CM_ "Toyota Yaris Hybrid 2014 (XP130, THS-II NoDSU) - reverse engineered from a candump (500kbps) captured on the";
CM_ "factory head-unit connector (28-pin, p/n 90980-12555, CAN-H=pin9/CAN-L=pin10), NOT the OBD-II diagnostic port.";
CM_ "Base messages taken from BogGyver/opendbc (tesla_unity_dev) toyota_nodsu_hybrid_pt_generated.dbc and empirically validated";
CM_ "against a real ~7min drive log (data/logs/session_0044.log). Additions for BRAKE_ANALOG (0x224) and";
CM_ "COMBO_METER_0x34 (0x618) are original findings from this project, not present in opendbc.";
CM_ "See docs/signal_findings.md for full validation methodology and confidence levels.";

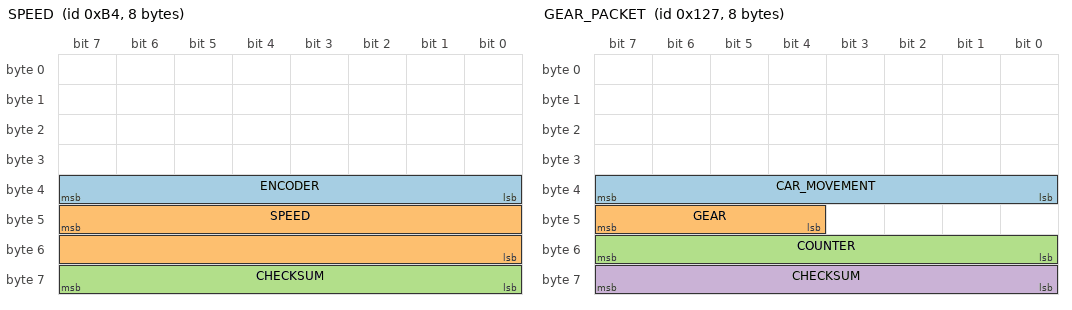
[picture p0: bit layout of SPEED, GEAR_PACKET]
BO_ 180 SPEED: 8 XXX
 SG_ ENCODER : 39|8@0+ (1,0) [0|255] "" XXX
 SG_ SPEED : 47|16@0+ (0.01,0) [0|250] "kph" XXX
 SG_ CHECKSUM : 63|8@0+ (1,0) [0|255] "" XXX

CM_ SG_ 180 SPEED "CONFIRMED. Validated against real 0->60->0 kph driving profile.";

BO_ 452 ENGINE_RPM: 8 XXX
 SG_ RPM : 7|16@0- (0.78125,0) [0|0] "rpm" XXX

CM_ SG_ 452 RPM "CONFIRMED. Oscillates 0/~1000-2000rpm matching ICE start/stop cycling typical of THS-II.";

BO_ 295 GEAR_PACKET: 8 XXX
 SG_ CAR_MOVEMENT : 39|8@0- (1,0) [0|255] "" XXX
 SG_ GEAR : 47|4@0+ (1,0) [0|15] "" XXX
 SG_ COUNTER : 55|8@0+ (1,0) [0|255] "" XXX
 SG_ CHECKSUM : 63|8@0+ (1,0) [0|255] "" XXX

VAL_ 295 GEAR 0 "P" 1 "R" 2 "N" 3 "D" 4 "B" ;
CM_ SG_ 295 GEAR "CONFIRMED, all 5 states observed across two independent logs. session_0044: P(0) 0-50.4s -> R(1) 50.4-60.1s -> D(3) 60.1s-end, with SPEED=0 while parked, a reverse bump (0->4.7kph) during the R phase and forward acceleration (0->10+kph) right after the D shift. session_0047: P(0) held ~98s at standstill -> N(2)->R(1)->N(2)->D(3) pull-out sequence -> D held for ~280s of real driving -> end-of-log full gear cycle R(1)->D(3)->B(4)->D(3)->N(2)->R(1)->D(3)->P(0), confirming B (Engine Brake) as well. NOTE: 0x127 was previously suspected to be a 'drive mode' counter; that counter is actually the CAR_MOVEMENT byte, a separate field in the same message.";

BO_ 560 BRAKE_MODULE2: 7 XXX
 SG_ BRAKE_PRESSED : 26|1@0+ (1,0) [0|1] "" XXX

CM_ SG_ 560 BRAKE_PRESSED "CONFIRMED. Transition timings correlate exactly with GEAR shifts and SPEED changes (brake held at standstill before/after each gear change).";

BO_ 548 BRAKE_ANALOG: 8 XXX
 SG_ BRAKE_VALUE : 32|16@0+ (1,0) [0|1023] "" XXX

CM_ BO_ 548 "STRONG HYPOTHESIS (not in any opendbc DBC - original finding). ID 0x224, not present in upstream Toyota DBCs (which define BRAKE_MODULE with pressure/position at 0x226, absent from this capture). Formula: value = (byte[4]<<8 | byte[5]), i.e. bits 32-47 as a big-endian 16-bit (effectively ~10-bit, max observed 537) quantity. Statistically: median=0 / mean=0.04 while BRAKE_PRESSED=0 (n=12027), median=62 / mean=154 / max=537 while BRAKE_PRESSED=1 (n=5731); 84% of pressed samples have value>5, 99.99% of released samples have value<=5. Strong correlation confirms this is a brake pedal analog signal (pressure and/or position), but exact physical units/scale are NOT confirmed.";

BO_ 581 GAS_PEDAL: 8 XXX
 SG_ GAS_PEDAL : 23|8@0+ (0.005,0) [0|1] "" XXX

CM_ SG_ 581 GAS_PEDAL "CONFIRMED. 0.0-0.35 (0-35%) range observed, closely tracking the accelerate/coast pattern of city driving and preceding each RPM/SPEED rise.";

BO_ 1553 UI_SETTING: 8 XXX
 SG_ UNITS : 26|2@0+ (1,0) [0|3] "" XXX
 SG_ ODOMETER : 43|20@0+ (1,0) [0|1048575] "" XXX

VAL_ 1553 UNITS 1 "km" 2 "miles" ;
CM_ SG_ 1553 ODOMETER "CONFIRMED but NOT remaining range. This is the TOTAL vehicle odometer (99552 -> 99555 km over the ~7min/~3km log, UNITS=km). No distance-to-empty / remaining-range signal or HV SOC% was found in this capture -- see docs/signal_findings.md section 2 for the negative-result justification.";

BO_ 1556 STEERING_LEVERS: 8 XXX
 SG_ TURN_SIGNALS : 29|2@0+ (1,0) [0|3] "" XXX
 SG_ HAZARD_LIGHT : 27|1@0+ (1,0) [0|1] "" XXX

VAL_ 1556 TURN_SIGNALS 3 "none" 2 "right" 1 "left" ;
CM_ SG_ 1556 TURN_SIGNALS "CONFIRMED. All 3 states (left/right/none) observed over the drive with plausible multi-second durations consistent with real indicator usage at turns.";

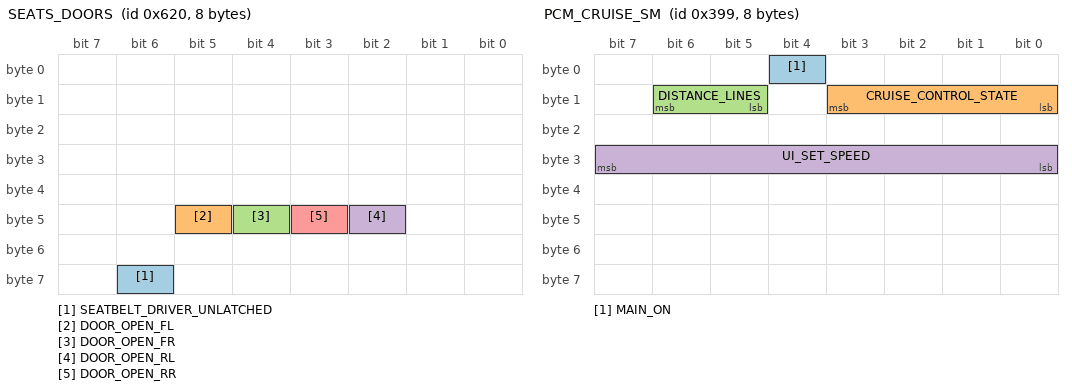
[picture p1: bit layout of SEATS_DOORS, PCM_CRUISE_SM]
BO_ 1568 SEATS_DOORS: 8 XXX
 SG_ SEATBELT_DRIVER_UNLATCHED : 62|1@0+ (1,0) [0|1] "" XXX
 SG_ DOOR_OPEN_FL : 45|1@0+ (1,0) [0|1] "" XXX
 SG_ DOOR_OPEN_FR : 44|1@0+ (1,0) [0|1] "" XXX
 SG_ DOOR_OPEN_RL : 42|1@0+ (1,0) [0|1] "" XXX
 SG_ DOOR_OPEN_RR : 43|1@0+ (1,0) [0|1] "" XXX

CM_ BO_ 1568 "CONFIRMED PRESENT, plausible (seatbelt toggles 0/1); doors never opened during this particular drive so DOOR_OPEN_* only show constant 0 in this log (not independently validated, but the message/bit layout is inherited verbatim from opendbc).";

BO_ 921 PCM_CRUISE_SM: 8 XXX
 SG_ MAIN_ON : 4|1@0+ (1,0) [0|1] "" XXX
 SG_ CRUISE_CONTROL_STATE : 11|4@0+ (1,0) [0|15] "" XXX
 SG_ DISTANCE_LINES : 14|2@0+ (1,0) [0|3] "" XXX
 SG_ UI_SET_SPEED : 31|8@0+ (1,0) [0|255] "" XXX

CM_ BO_ 921 "PRESENT but INACTIVE for the whole log (all-zero) -- cruise control was never engaged during capture, so fields could not be behaviourally validated beyond confirming the message exists at the expected ID/layout.";

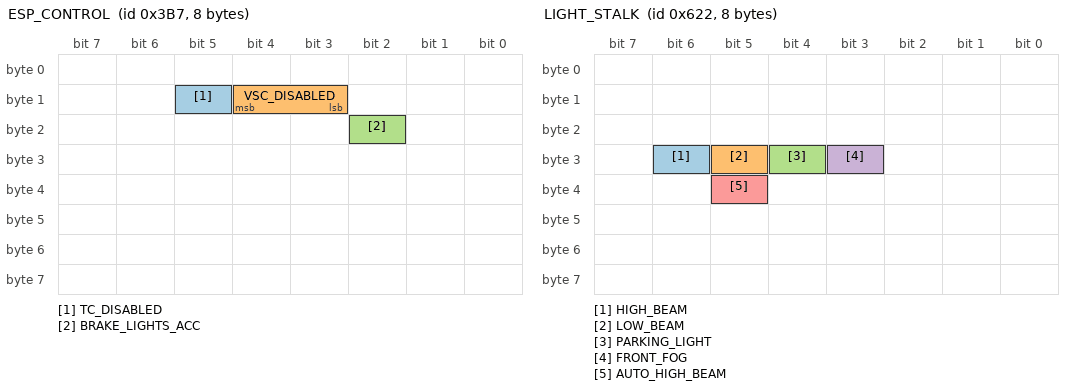
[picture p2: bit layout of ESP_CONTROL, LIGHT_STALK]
BO_ 951 ESP_CONTROL: 8 XXX
 SG_ TC_DISABLED : 13|1@0+ (1,0) [0|1] "" XXX
 SG_ VSC_DISABLED : 12|2@0+ (1,0) [0|1] "" XXX
 SG_ BRAKE_LIGHTS_ACC : 18|1@0+ (1,0) [0|1] "" XXX

CM_ BO_ 951 "PRESENT but INACTIVE for the whole log (no VSC/TC intervention occurred during this calm drive).";

BO_ 1570 LIGHT_STALK: 8 XXX
 SG_ HIGH_BEAM : 30|1@0+ (1,0) [0|1] "" XXX
 SG_ LOW_BEAM : 29|1@0+ (1,0) [0|1] "" XXX
 SG_ PARKING_LIGHT : 28|1@0+ (1,0) [0|1] "" XXX
 SG_ FRONT_FOG : 27|1@0+ (1,0) [0|1] "" XXX
 SG_ AUTO_HIGH_BEAM : 37|1@0+ (1,0) [0|1] "" XXX

CM_ BO_ 1570 "CONFIRMED PRESENT; LOW_BEAM/PARKING_LIGHT toggled 0/1 during the log, plausible.";

BO_ 1560 COMBO_METER_0x34: 8 XXX
 SG_ TEMP_RAW : 24|8@0+ (1,0) [0|255] "" XXX

CM_ BO_ 1560 "STRONG HYPOTHESIS, original finding (not in any opendbc DBC). ID 0x618 belongs to a family of low-frequency (~0.1Hz) 'combination meter' multiplex messages (0x610-0x615, 0x618-0x61c) where byte[0] is a constant per-ID parameter-index tag (unrelated to numeric CAN ID order). byte[3] (TEMP_RAW here) climbs monotonically and smoothly from 0 at cold start/idle (t=0-64s, matches GEAR=P) to a plateau around 230-240 by t=350-430s, in lock-step with the engine actually running (matches GEAR shifting to R/D at t=50-60s). This is the textbook shape of an engine coolant warm-up curve reaching thermostat-regulated operating temperature after ~5 minutes of driving. Candidate formula (UNCONFIRMED SCALE): temp_C = TEMP_RAW * 0.375, which places the plateau at a plausible 90 deg C; this scale factor is a best-fit guess, not derived from a reference thermometer reading. Could equally be transmission/CVT fluid temperature rather than coolant -- not distinguishable from this data alone.";

BO_ 928 FUEL_LEVEL: 8 XXX
 SG_ FUEL_RAW : 63|8@0+ (1,0) [0|255] "" XXX

CM_ BO_ 928 "STRONG HYPOTHESIS, original finding (not in any opendbc DBC). ID 0x3A0, byte[7] is the only non-zero byte in an otherwise all-zero 8-byte message, transmitted at a steady 10Hz. In two independent drives it decreases slowly and almost monotonically for the whole session (session_0044: 61->53 over 350s; session_0047: 58->52 over 430s), with small back-and-forth noise between adjacent values (consistent with a fuel sender sloshing) but never rising or wrapping around. Textbook shape for a slowly-consumed fuel level. Scale/units NOT confirmed (no known full-tank reference reading yet) -- do not trust FUEL_RAW as liters or % as-is. FOLLOW-UP CHECK: the raw decrease rate correlates much better with elapsed wall-clock/engine-on time (~54s/unit in session_0044 vs ~72s/unit in session_0047, same order of magnitude) than with distance driven via ODOMETER (~1.1km/unit in session_0044 vs ~0.17km/unit in session_0047, a 7x mismatch) -- this rules out 'distance-to-empty in km' as the meaning of this byte and is more consistent with real fuel burn during low-speed stop-and-go driving (lots of idling/engine-on time, little distance). Full-scale/linearity to the 36L tank still unconfirmed -- would need a known-liters reference reading (e.g. right after a fill-up) to calibrate.";

BO_ 953 TEMP_RAW2: 3 XXX
 SG_ TEMP2_RAW : 7|8@0+ (1,0) [0|255] "" XXX

CM_ BO_ 953 "STRONG HYPOTHESIS, original finding (not in any opendbc DBC). ID 0x3B9, dlc=3, byte[1] and byte[2] always 0x00 -- only byte[0] (TEMP2_RAW) is active, transmitted at ~1Hz. In both independent logs byte[0] climbs smoothly and nearly monotonically from a stable starting value early in the drive to a plateau late in the drive (session_0044: 103->173 over ~430s, plateauing/oscillating in a tight band from ~t=350s; session_0047: 110(dips to 110 first)->160 over ~440s, similar late-session plateau/oscillation). Correlates very strongly with elapsed time (r=0.945 / r=0.968) AND with the already-confirmed TEMP_RAW (0x618 byte3) warm-up curve (r=0.950 / r=0.969 respectively), including a shared inflection point where both curves flatten out around the same point in the drive -- not just two independently-monotonic trends. Weak/negative correlation with instantaneous RPM (r=-0.16 / r=-0.10) rules out a fast-responding signal; consistent with a second, more thermally-lagged temperature sensor (larger thermal mass than coolant -- candidate: engine oil, CVT/transaxle fluid, or HV battery pack temperature). Plateau value differs between the two logs (173 vs 160) unlike coolant temp which is thermostat-regulated to a fixed setpoint -- this is actually consistent with a less tightly-regulated thermal mass whose final temperature depends on trip-specific load/ambient conditions. NOT distinguishable from this data alone which physical sensor this is; no scale/formula proposed.";

BO_ 1186 CHASSIS_BRAKE2: 8 XXX
 SG_ BRAKE2_FIELD_A : 31|8@0+ (1,0) [0|255] "" XXX
 SG_ BRAKE2_FIELD_B : 47|8@0+ (1,0) [0|255] "" XXX

CM_ BO_ 1186 "TENTATIVE, original finding (not in any opendbc DBC) -- explicitly NOT a battery/SOC candidate despite superficially matching a charge/discharge pattern. ID 0x4A2, byte[3] (BRAKE2_FIELD_A) and byte[5] (BRAKE2_FIELD_B) both correlate strongly with the already-confirmed BRAKE_ANALOG (0x224 byte[4:6]): byte[3] r=-0.93/-0.79, byte[5] r=+0.93/+0.79 across the two logs, i.e. far stronger than their correlation with GAS_PEDAL (|r| 0.2-0.6) or with each other's brake-anticorrelation pattern alone would suggest by coincidence. Also correlates with SPEED (byte[3] r=+0.60/+0.22), which a pure battery-power signal would not be expected to do. Most likely interpretation: a second brake/deceleration-related telemetry pair broadcast by a different ECU (e.g. ABS/VSC wheel-brake pressure or measured deceleration), not an independent physical quantity. Recorded here mainly so this ID is not re-investigated as a false-lead 'battery power' candidate in a future search -- see docs/signal_findings.md section 2 for the full reasoning on why this was ruled out as SOC.";

CM_ "=== MANDATORY SIGNALS NOT FOUND (see docs/signal_findings.md for full explanation) ===";
CM_ "Remaining range (km) / HV battery SOC%: NOT FOUND. Prius-family reference docs (EAA-PHEV wiki, PriusChat Gen2 CAN/OBD2 PID list) show HV SOC only available via (a) solicited UDS diagnostic requests to the Battery ECU (0x7E2/0x7E3, Mode 21 PIDs C3/CE), not broadcast periodically, or (b) the unsolicited 0x0529 message (MFD SOC bars + EV-mode bits). Neither appears in this capture, taken from the head-unit's own CAN-H/CAN-L pins (same bus the aftermarket Android head unit's canbus box uses to display SOC/EV-mode). Since that connector otherwise carries the same broadcast set expected on the main HS-CAN, the leading hypothesis is now that the aftermarket box obtains SOC/EV-mode via active diagnostic polling, not passive listening -- not that it sits on a separate unreachable bus. CONFIRMED (this round): zero frames in the 0x700-0x7FF UDS/ISO-TP diagnostic ID range in either log; a systematic cross-log-validated scan of every remaining (id, byte-pair) 16-bit combination and every (id, byte, nibble/top-3-bit) sub-byte field found no candidate with plausible bounded SOC-like dynamics that wasn't better explained as a known duplicate (gas pedal, brake analog) or a non-physical counter. Web research (this round) found no other reverse-engineered repo that has solved SOC/fuel for this exact NoDSU hybrid ID scheme, and confirmed neither 0x3A0 nor 0x4A8 exist in any known upstream opendbc DBC -- this is genuinely undocumented territory, not a known-solved problem we're missing. To be confirmed with a capture taken in parallel with the aftermarket box running, or (more promising per this round's research into the box's likely UART protocol) a logic-analyzer/UART capture on the box's headunit-side output.";
CM_ "EV mode (explicit bit): NOT FOUND, same as above. PROXY IMPLEMENTED instead: RPM(0x1C4) < 50 while SPEED(0x0B4) > 1 kph. Over this log, 53.0% of time spent moving matches this proxy, with 23 transitions in/out of it -- consistent with typical THS-II engine start/stop cycling during city driving. This is a derived/inferred signal, not a decoded CAN bit.";
